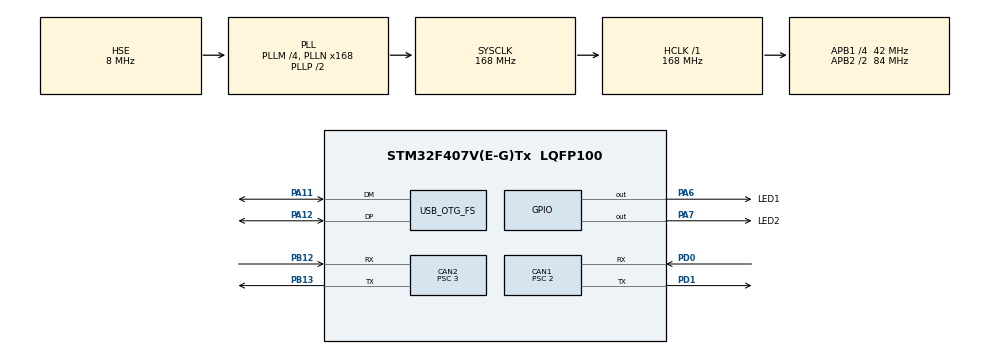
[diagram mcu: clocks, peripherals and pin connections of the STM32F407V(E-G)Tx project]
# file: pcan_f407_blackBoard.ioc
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CAN1.BS1=CAN_BS1_16TQ
CAN1.BS2=CAN_BS2_4TQ
CAN1.CalculateBaudRate=1000000
CAN1.CalculateTimeBit=1000
CAN1.CalculateTimeQuantum=47.61904761904762
CAN1.Prescaler=2
CAN1.SJW=CAN_SJW_1TQ
CAN2.BS1=CAN_BS1_10TQ
CAN2.BS2=CAN_BS2_3TQ
CAN2.CalculateBaudRate=1000000
CAN2.CalculateTimeBit=1000
CAN2.CalculateTimeQuantum=71.42857142857143
CAN2.Prescaler=3
Mcu.Family=STM32F4
Mcu.Name=STM32F407V(E-G)Tx
Mcu.Package=LQFP100
NVIC.CAN1_RX0_IRQn=true\:0\:0\:false\:false\:true\:true\:true\:true
NVIC.CAN1_RX1_IRQn=true\:0\:0\:false\:false\:true\:true\:true\:true
NVIC.CAN1_SCE_IRQn=true\:0\:0\:false\:false\:true\:true\:true\:true
NVIC.CAN1_TX_IRQn=true\:0\:0\:false\:false\:true\:true\:true\:true
NVIC.CAN2_RX0_IRQn=true\:0\:0\:false\:false\:true\:true\:true\:true
NVIC.CAN2_RX1_IRQn=true\:0\:0\:false\:false\:true\:true\:true\:true
NVIC.CAN2_SCE_IRQn=true\:0\:0\:false\:false\:true\:true\:true\:true
NVIC.CAN2_TX_IRQn=true\:0\:0\:false\:false\:true\:true\:true\:true
NVIC.OTG_FS_IRQn=true\:0\:0\:false\:false\:true\:true\:true\:true
NVIC.PriorityGroup=NVIC_PRIORITYGROUP_4
PA11.Mode=Device_Only
PA11.Signal=USB_OTG_FS_DM
PA12.Mode=Device_Only
PA12.Signal=USB_OTG_FS_DP
PA13.Mode=Serial_Wire
PA13.Signal=SYS_JTMS-SWDIO
PA14.Mode=Serial_Wire
PA14.Signal=SYS_JTCK-SWCLK
PA6.GPIO_Label=LED1
PA6.Signal=GPIO_Output
PA7.GPIO_Label=LED2
PA7.Signal=GPIO_Output
PB12.Mode=CAN_Activate
PB12.Signal=CAN2_RX
PB13.Mode=CAN_Activate
PB13.Signal=CAN2_TX
PD0.Mode=CAN_Activate
PD0.Signal=CAN1_RX
PD1.Mode=CAN_Activate
PD1.Signal=CAN1_TX
PH0-OSC_IN.Mode=HSE-External-Oscillator
PH0-OSC_IN.Signal=RCC_OSC_IN
PH1-OSC_OUT.Mode=HSE-External-Oscillator
PH1-OSC_OUT.Signal=RCC_OSC_OUT
ProjectManager.HeapSize=0x200
ProjectManager.StackSize=0x400
ProjectManager.TargetToolchain=STM32CubeIDE
RCC.48MHZClocksFreq_Value=48000000
RCC.AHBFreq_Value=168000000
RCC.APB1CLKDivider=RCC_HCLK_DIV4
RCC.APB1Freq_Value=42000000
RCC.APB1TimFreq_Value=84000000
RCC.APB2CLKDivider=RCC_HCLK_DIV2
RCC.APB2Freq_Value=84000000
RCC.APB2TimFreq_Value=168000000
RCC.CortexFreq_Value=168000000
RCC.EnbaleCSS=true
RCC.HCLKFreq_Value=168000000
RCC.HSE_VALUE=8000000
RCC.HSI_VALUE=16000000
RCC.LSE_VALUE=32768
RCC.PLLM=4
RCC.PLLN=168
RCC.PLLQ=7
RCC.SYSCLKFreq_VALUE=168000000
RCC.SYSCLKSource=RCC_SYSCLKSOURCE_PLLCLK
RCC.VCOOutputFreq_Value=336000000
TIM2.Prescaler=83
USB_OTG_FS.VirtualMode=Device_Only
VP_TIM2_VS_ClockSourceINT.Mode=Internal
board=custom

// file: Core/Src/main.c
/* USER CODE BEGIN Header */
/**
  ******************************************************************************
  * @file           : main.c
  * @brief          : Main program body
  ******************************************************************************
  * @attention
  *
  * Copyright (c) 2024 STMicroelectronics.
  * All rights reserved.
  *
  * This software is licensed under terms that can be found in the LICENSE file
  * in the root directory of this software component.
  * If no LICENSE file comes with this software, it is provided AS-IS.
  *
  ******************************************************************************
  */
/* USER CODE END Header */
#include "main.h"
#include "can.h"
#include "tim.h"
#include "usb_otg.h"
#include "gpio.h"

/* USER CODE BEGIN Includes */
#include "pcanpro_timestamp.h"
#include "pcanpro_can.h"
#include "pcanpro_led.h"
#include "pcanpro_protocol.h"
#include "usb_device.h"

/* USER CODE END Includes */

void SystemClock_Config(void);

int main(void)
{

  /* MCU Configuration--------------------------------------------------------*/

  /* Reset of all peripherals, Initializes the Flash interface and the Systick. */
  HAL_Init();

  /* Configure the system clock */
  SystemClock_Config();

  /* Initialize all configured peripherals */
  MX_GPIO_Init();
  MX_CAN1_Init();
  MX_CAN2_Init();
  MX_USB_OTG_FS_PCD_Init();
  MX_TIM2_Init();
  /* USER CODE BEGIN 2 */

  pcan_timestamp_init();
  pcan_led_init();
  pcan_led_set_mode( LED_STAT, LED_MODE_BLINK_FAST, 0xFFFFFFFF );
  pcan_protocol_init();
  pcan_usb_device_init();
  /* USER CODE END 2 */

  /* Infinite loop */
  /* USER CODE BEGIN WHILE */
  while (1)
  {
	    pcan_usb_device_poll();
	    pcan_can_poll();
	    pcan_protocol_poll();
	    pcan_led_poll();
    /* USER CODE END WHILE */

  }
}

void SystemClock_Config(void)
{
  RCC_OscInitTypeDef RCC_OscInitStruct = {0};
  RCC_ClkInitTypeDef RCC_ClkInitStruct = {0};

  /** Configure the main internal regulator output voltage
  */
  __HAL_RCC_PWR_CLK_ENABLE();
  __HAL_PWR_VOLTAGESCALING_CONFIG(PWR_REGULATOR_VOLTAGE_SCALE1);

  /** Initializes the RCC Oscillators according to the specified parameters
  * in the RCC_OscInitTypeDef structure.
  */
  RCC_OscInitStruct.OscillatorType = RCC_OSCILLATORTYPE_HSE;
  RCC_OscInitStruct.HSEState = RCC_HSE_ON;
  RCC_OscInitStruct.PLL.PLLState = RCC_PLL_ON;
  RCC_OscInitStruct.PLL.PLLSource = RCC_PLLSOURCE_HSE;
  RCC_OscInitStruct.PLL.PLLM = 4;
  RCC_OscInitStruct.PLL.PLLN = 168;
  RCC_OscInitStruct.PLL.PLLP = RCC_PLLP_DIV2;
  RCC_OscInitStruct.PLL.PLLQ = 7;
  if (HAL_RCC_OscConfig(&RCC_OscInitStruct) != HAL_OK)
  {
    Error_Handler();
  }

  /** Initializes the CPU, AHB and APB buses clocks
  */
  RCC_ClkInitStruct.ClockType = RCC_CLOCKTYPE_HCLK|RCC_CLOCKTYPE_SYSCLK
                              |RCC_CLOCKTYPE_PCLK1|RCC_CLOCKTYPE_PCLK2;
  RCC_ClkInitStruct.SYSCLKSource = RCC_SYSCLKSOURCE_PLLCLK;
  RCC_ClkInitStruct.AHBCLKDivider = RCC_SYSCLK_DIV1;
  RCC_ClkInitStruct.APB1CLKDivider = RCC_HCLK_DIV4;
  RCC_ClkInitStruct.APB2CLKDivider = RCC_HCLK_DIV2;

  if (HAL_RCC_ClockConfig(&RCC_ClkInitStruct, FLASH_LATENCY_5) != HAL_OK)
  {
    Error_Handler();
  }

  /** Enables the Clock Security System
  */
  HAL_RCC_EnableCSS();
}

void Error_Handler(void)
{
  __disable_irq();
  while (1)
  {
  }
}
